# S32K116 register map
Vendor: NXP; Series: S32K; File version: 1.6
CPU: CM0PLUS r0p0, little endian, MPU, FPU, 2 interrupt priority bits
Registers are 32-bit, read-write, reset 0x0 unless marked. A register's access mark holds for its fields unless they carry their own. Offsets are from the block's base; [hi:lo] are bit positions.

## FTFC
Base 0x40020000; register names take the prefix FTFC_
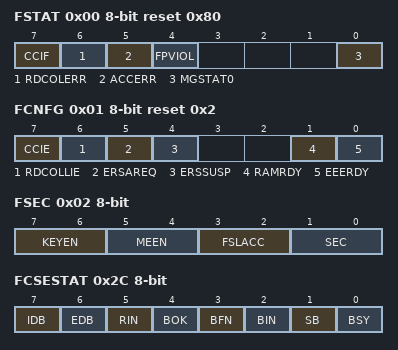
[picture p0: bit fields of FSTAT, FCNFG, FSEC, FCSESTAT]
0x00 FSTAT 8-bit reset 0x80 — Flash Status Register
  [7] CCIF — Command Complete Interrupt Flag
  [6] RDCOLERR — FTFC Read Collision Error Flag
    0=No collision error detected; 1=Collision error detected
  [5] ACCERR — Flash Access Error Flag
    0=No access error detected; 1=Access error detected
  [4] FPVIOL — Flash Protection Violation Flag
    0=No protection violation detected; 1=Protection violation detected
  [0] MGSTAT0 ro — Memory Controller Command Completion Status Flag
0x01 FCNFG 8-bit reset 0x2 — Flash Configuration Register
  [7] CCIE — Command Complete Interrupt Enable
    0=Command complete interrupt disabled; 1=Command complete interrupt enabled. An interrupt request is generated whenever the FSTAT[CCIF] flag is set.
  [6] RDCOLLIE — Read Collision Error Interrupt Enable
    0=Read collision error interrupt disabled; 1=Read collision error interrupt enabled. An interrupt request is generated whenever an FTFC read collision error is detected (see the description of FSTAT[RDCOLERR]).
  [5] ERSAREQ ro — Erase All Request
    0=No request or request complete
  [4] ERSSUSP — Erase Suspend
    0=No suspend requested; 1=Suspend the current Erase Flash Sector command execution
  [1] RAMRDY ro — RAM Ready
  [0] EEERDY ro
0x02 FSEC 8-bit ro reset not defined — Flash Security Register
  [7:6] KEYEN — Backdoor Key Security Enable
    0=Backdoor key access disabled; 1=Backdoor key access disabled (preferred KEYEN state to disable backdoor key access); 2=Backdoor key access enabled; 3=Backdoor key access disabled
  [5:4] MEEN — Mass Erase Enable Bits
    0=Mass erase is enabled; 1=Mass erase is enabled; 3=Mass erase is enabled
  [3:2] FSLACC — Factory Failure Analysis Access Code
    0=Factory access granted; 3=Factory access granted
  [1:0] SEC — Flash Security
    2=MCU security status is unsecure (The standard shipping condition of the FTFC is unsecure.)
0x03 FOPT 8-bit ro reset not defined — Flash Option Register
  [7:0] OPT — Nonvolatile Option
0x04 FCCOB3 8-bit — Flash Common Command Object Registers
  [7:0] CCOBn
0x05 FCCOB2 8-bit — Flash Common Command Object Registers
  [7:0] CCOBn
0x06 FCCOB1 8-bit — Flash Common Command Object Registers
  [7:0] CCOBn
0x07 FCCOB0 8-bit — Flash Common Command Object Registers
  [7:0] CCOBn
0x08 FCCOB7 8-bit — Flash Common Command Object Registers
  [7:0] CCOBn
0x09 FCCOB6 8-bit — Flash Common Command Object Registers
  [7:0] CCOBn
0x0A FCCOB5 8-bit — Flash Common Command Object Registers
  [7:0] CCOBn
0x0B FCCOB4 8-bit — Flash Common Command Object Registers
  [7:0] CCOBn
0x0C FCCOBB 8-bit — Flash Common Command Object Registers
  [7:0] CCOBn
0x0D FCCOBA 8-bit — Flash Common Command Object Registers
  [7:0] CCOBn
0x0E FCCOB9 8-bit — Flash Common Command Object Registers
  [7:0] CCOBn
0x0F FCCOB8 8-bit — Flash Common Command Object Registers
  [7:0] CCOBn
0x10 FPROT3 8-bit reset not defined — Program Flash Protection Registers
  [7:0] PROT — Program Flash Region Protect
0x11 FPROT2 8-bit reset not defined — Program Flash Protection Registers
  [7:0] PROT — Program Flash Region Protect
0x12 FPROT1 8-bit reset not defined — Program Flash Protection Registers
  [7:0] PROT — Program Flash Region Protect
0x13 FPROT0 8-bit reset not defined — Program Flash Protection Registers
  [7:0] PROT — Program Flash Region Protect
0x16 FEPROT 8-bit reset not defined — EEPROM Protection Register
  [7:0] EPROT — EEPROM Region Protect
0x17 FDPROT 8-bit reset not defined — Data Flash Protection Register
  [7:0] DPROT — Data Flash Region Protect
    0=Data Flash region is protected; 1=Data Flash region is not protected
0x2C FCSESTAT 8-bit ro — Flash CSEc Status Register
  [7] IDB — Internal Debug
  [6] EDB — External Debug
  [5] RIN — Random Number Generator Initialized
  [4] BOK — Secure Boot OK
  [3] BFN — Secure Boot Finished
  [2] BIN — Secure Boot Initialization
  [1] SB — Secure Boot
  [0] BSY — Busy
0x2E FERSTAT 8-bit — Flash Error Status Register
  [1] DFDIF — Double Bit Fault Detect Interrupt Flag
    0=Double bit fault not detected during a valid flash read access from the platform flash controller; 1=Double bit fault detected (or FERCNFG[FDFD] is set) during a valid flash read access from the platform flash controller
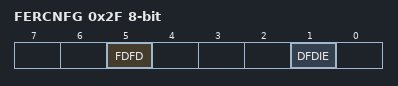
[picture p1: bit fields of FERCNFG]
0x2F FERCNFG 8-bit — Flash Error Configuration Register
  [5] FDFD — Force Double Bit Fault Detect
    0=FERSTAT[DFDIF] sets only if a double bit fault is detected during read access from the platform flash controller; 1=FERSTAT[DFDIF] sets during any valid flash read access from the platform flash controller. An interrupt request is generated if the DFDIE bit is set.
  [1] DFDIE — Double Bit Fault Detect Interrupt Enable
    0=Double bit fault detect interrupt disabled; 1=Double bit fault detect interrupt enabled. An interrupt request is generated whenever the FERSTAT[DFDIF] flag is set.

## Notices in the file
Redistribution and use in source and binary forms, with or without modification,
are permitted provided that the following conditions are met:
o Redistributions of source code must retain the above copyright notice, this list
of conditions and the following disclaimer.
o Redistributions in binary form must reproduce the above copyright notice, this
list of conditions and the following disclaimer in the documentation and/or
other materials provided with the distribution.
o Neither the name of Freescale Semiconductor, Inc. nor the names of its
contributors may be used to endorse or promote products derived from this
software without specific prior written permission.
THIS SOFTWARE IS PROVIDED BY THE COPYRIGHT HOLDERS AND CONTRIBUTORS "AS IS" AND
ANY EXPRESS OR IMPLIED WARRANTIES, INCLUDING, BUT NOT LIMITED TO, THE IMPLIED
WARRANTIES OF MERCHANTABILITY AND FITNESS FOR A PARTICULAR PURPOSE ARE
DISCLAIMED. IN NO EVENT SHALL THE COPYRIGHT HOLDER OR CONTRIBUTORS BE LIABLE FOR
ANY DIRECT, INDIRECT, INCIDENTAL, SPECIAL, EXEMPLARY, OR CONSEQUENTIAL DAMAGES
(INCLUDING, BUT NOT LIMITED TO, PROCUREMENT OF SUBSTITUTE GOODS OR SERVICES;
LOSS OF USE, DATA, OR PROFITS; OR BUSINESS INTERRUPTION) HOWEVER CAUSED AND ON
ANY THEORY OF LIABILITY, WHETHER IN CONTRACT, STRICT LIABILITY, OR TORT
(INCLUDING NEGLIGENCE OR OTHERWISE) ARISING IN ANY WAY OUT OF THE USE OF THIS
SOFTWARE, EVEN IF ADVISED OF THE POSSIBILITY OF SUCH DAMAGE.
